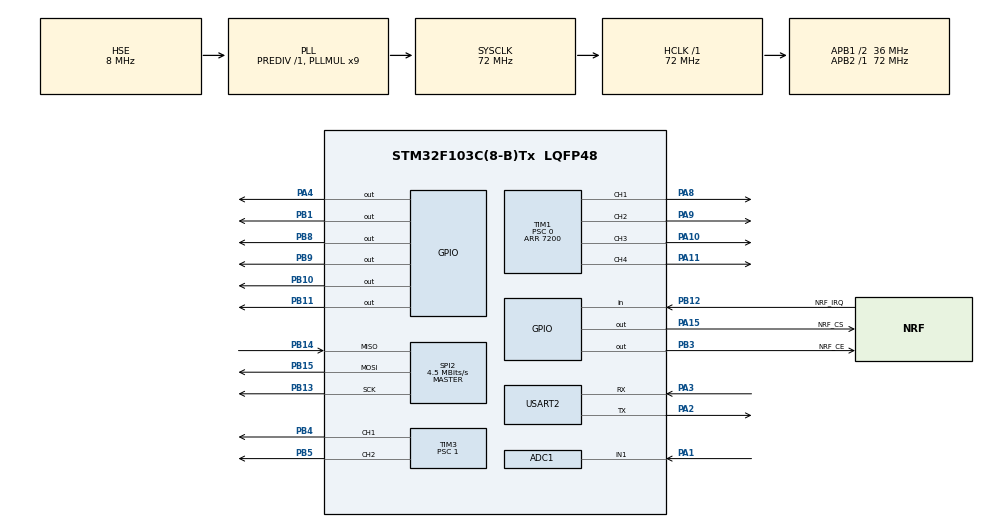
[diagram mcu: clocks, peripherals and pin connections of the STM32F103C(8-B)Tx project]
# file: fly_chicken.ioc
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ADC1.Channel-0\#ChannelRegularConversion=ADC_CHANNEL_1
ADC1.NbrOfConversionFlag=1
ADC1.Rank-0\#ChannelRegularConversion=1
ADC1.SamplingTime-0\#ChannelRegularConversion=ADC_SAMPLETIME_239CYCLES_5
ADC1.master=1
Mcu.Family=STM32F1
Mcu.Name=STM32F103C(8-B)Tx
Mcu.Package=LQFP48
NVIC.PriorityGroup=NVIC_PRIORITYGROUP_4
NVIC.TIM1_UP_IRQn=true\:0\:0\:false\:false\:true\:true\:true\:true
NVIC.TIM2_IRQn=true\:0\:0\:false\:false\:true\:true\:true\:true
PA1.Signal=ADCx_IN1
PA10.Signal=S_TIM1_CH3
PA11.Signal=S_TIM1_CH4
PA13.Mode=Serial_Wire
PA13.Signal=SYS_JTMS-SWDIO
PA14.Mode=Serial_Wire
PA14.Signal=SYS_JTCK-SWCLK
PA15.GPIO_Label=NRF_CS
PA15.GPIO_Speed=GPIO_SPEED_FREQ_HIGH
PA15.PinState=GPIO_PIN_SET
PA15.Signal=GPIO_Output
PA2.Mode=Asynchronous
PA2.Signal=USART2_TX
PA3.Mode=Asynchronous
PA3.Signal=USART2_RX
PA4.Signal=GPIO_Output
PA8.Signal=S_TIM1_CH1
PA9.Signal=S_TIM1_CH2
PB1.GPIO_Speed=GPIO_SPEED_FREQ_LOW
PB1.PinState=GPIO_PIN_RESET
PB1.Signal=GPIO_Output
PB10.Signal=GPIO_Output
PB11.Signal=GPIO_Output
PB12.GPIO_Label=NRF_IRQ
PB12.GPIO_PuPd=GPIO_PULLUP
PB12.Signal=GPIO_Input
PB13.Mode=Full_Duplex_Master
PB13.Signal=SPI2_SCK
PB14.Mode=Full_Duplex_Master
PB14.Signal=SPI2_MISO
PB15.Mode=Full_Duplex_Master
PB15.Signal=SPI2_MOSI
PB3.GPIO_Label=NRF_CE
PB3.GPIO_Speed=GPIO_SPEED_FREQ_HIGH
PB3.PinState=GPIO_PIN_SET
PB3.Signal=GPIO_Output
PB4.Signal=S_TIM3_CH1
PB5.Signal=S_TIM3_CH2
PB8.Signal=GPIO_Output
PB9.Signal=GPIO_Output
PD0-OSC_IN.Mode=HSE-External-Oscillator
PD0-OSC_IN.Signal=RCC_OSC_IN
PD1-OSC_OUT.Mode=HSE-External-Oscillator
PD1-OSC_OUT.Signal=RCC_OSC_OUT
ProjectManager.HeapSize=0x200
ProjectManager.StackSize=0x400
ProjectManager.TargetToolchain=MDK-ARM V5.32
RCC.AHBFreq_Value=72000000
RCC.APB1CLKDivider=RCC_HCLK_DIV2
RCC.APB1Freq_Value=36000000
RCC.APB1TimFreq_Value=72000000
RCC.APB2Freq_Value=72000000
RCC.APB2TimFreq_Value=72000000
RCC.HCLKFreq_Value=72000000
RCC.PLLMUL=RCC_PLL_MUL9
RCC.PLLSourceVirtual=RCC_PLLSOURCE_HSE
RCC.SYSCLKFreq_VALUE=72000000
RCC.SYSCLKSource=RCC_SYSCLKSOURCE_PLLCLK
RCC.USBFreq_Value=72000000
SH.ADCx_IN1.0=ADC1_IN1,IN1
SH.S_TIM1_CH1.0=TIM1_CH1,PWM Generation1 CH1
SH.S_TIM1_CH2.0=TIM1_CH2,PWM Generation2 CH2
SH.S_TIM1_CH3.0=TIM1_CH3,PWM Generation3 CH3
SH.S_TIM1_CH4.0=TIM1_CH4,PWM Generation4 CH4
SH.S_TIM3_CH1.0=TIM3_CH1,PWM Generation1 CH1
SH.S_TIM3_CH2.0=TIM3_CH2,PWM Generation2 CH2
SPI2.BaudRatePrescaler=SPI_BAUDRATEPRESCALER_8
SPI2.CalculateBaudRate=4.5 MBits/s
SPI2.Direction=SPI_DIRECTION_2LINES
SPI2.Mode=SPI_MODE_MASTER
SPI2.VirtualType=VM_MASTER
TIM1.AutoReloadPreload=TIM_AUTORELOAD_PRELOAD_ENABLE
TIM1.Channel-PWM\ Generation1\ CH1=TIM_CHANNEL_1
TIM1.Channel-PWM\ Generation2\ CH2=TIM_CHANNEL_2
TIM1.Channel-PWM\ Generation3\ CH3=TIM_CHANNEL_3
TIM1.Channel-PWM\ Generation4\ CH4=TIM_CHANNEL_4
TIM1.OCPolarity_1=TIM_OCPOLARITY_HIGH
TIM1.OCPolarity_2=TIM_OCPOLARITY_HIGH
TIM1.OCPolarity_3=TIM_OCPOLARITY_HIGH
TIM1.OCPolarity_4=TIM_OCPOLARITY_HIGH
TIM1.Period=7200
TIM1.Prescaler=0
TIM1.Pulse-PWM\ Generation1\ CH1=200
TIM1.Pulse-PWM\ Generation2\ CH2=200
TIM1.Pulse-PWM\ Generation3\ CH3=200
TIM1.Pulse-PWM\ Generation4\ CH4=200
TIM2.AutoReloadPreload=TIM_AUTORELOAD_PRELOAD_ENABLE
TIM2.Period=1000
TIM2.Prescaler=71
TIM3.Channel-PWM\ Generation1\ CH1=TIM_CHANNEL_1
TIM3.Channel-PWM\ Generation2\ CH2=TIM_CHANNEL_2
TIM3.Period=1000
TIM3.Prescaler=1
TIM3.Pulse-PWM\ Generation1\ CH1=500
TIM3.Pulse-PWM\ Generation2\ CH2=500
TIM4.Prescaler=71
USART2.VirtualMode=VM_ASYNC
VP_TIM1_VS_ClockSourceINT.Mode=Internal
VP_TIM2_VS_ClockSourceINT.Mode=Internal
VP_TIM3_VS_ClockSourceINT.Mode=Internal
VP_TIM4_VS_ClockSourceINT.Mode=Internal
board=custom

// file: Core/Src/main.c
/* USER CODE BEGIN Header */
/**
  ******************************************************************************
  * @file           : main.c
  * @brief          : Main program body
  ******************************************************************************
  * @attention
  *
  * Copyright (c) 2023 STMicroelectronics.
  * All rights reserved.
  *
  * This software is licensed under terms that can be found in the LICENSE file
  * in the root directory of this software component.
  * If no LICENSE file comes with this software, it is provided AS-IS.
  *
  ******************************************************************************
  */
/* USER CODE END Header */
#include "main.h"
#include "adc.h"
#include "spi.h"
#include "tim.h"
#include "usart.h"
#include "gpio.h"

void SystemClock_Config(void);

int main(void)
{

  /* MCU Configuration--------------------------------------------------------*/

  /* Reset of all peripherals, Initializes the Flash interface and the Systick. */
  HAL_Init();

  /* Configure the system clock */
  SystemClock_Config();

  /* USER CODE BEGIN SysInit */
// 初始化IO，防止PB3不能使用作为LED，PB4用于频率输出
//// 注意：修改前需要确保AFIO配置正确
// AFIO->MAPR = 0X02000000; // 使能复用功能，关闭JTAG保留SWD，释放PB3和PB4端口，用于自定义功能（参考STM32F103手册第118页）

  /* USER CODE END SysInit */

  /* Initialize all configured peripherals */
  MX_GPIO_Init();
  MX_TIM2_Init();
  MX_TIM3_Init();
  MX_USART2_UART_Init();
  MX_TIM4_Init();
  MX_TIM1_Init();
  MX_SPI2_Init();
  MX_ADC1_Init();
  /* USER CODE BEGIN 2 */
  HAL_TIM_Base_Start(&htim4);// 启动定时器4，用作普通定时
  HAL_TIM_Base_Start_IT(&htim2);//��ʱ��һ1ms�ж������������
	HAL_TIM_PWM_Start(&htim1,TIM_CHANNEL_1);
	HAL_TIM_PWM_Start(&htim1,TIM_CHANNEL_2);
	HAL_TIM_PWM_Start(&htim1,TIM_CHANNEL_3);
	HAL_TIM_PWM_Start(&htim1,TIM_CHANNEL_4);
  Motor_Set_Duty(0,0,0,0);

  printf("hallo\r\n");

   // *************************** 任务初始化
	 HAL_Delay(2000);
	 ALL_Init();
	 HAL_Delay(1000);
   MY_Task_Begin();         // 任务开始
//	 Motor_Set_Duty(100,100,100,100);

//    __HAL_TIM_SET_COMPARE(&htim1,TIM_CHANNEL_1,800);// 电机1初始占空比0
//		__HAL_TIM_SET_COMPARE(&htim1,TIM_CHANNEL_2,800);//m2
//		__HAL_TIM_SET_COMPARE(&htim1,TIM_CHANNEL_3,800);//m3
//		__HAL_TIM_SET_COMPARE(&htim1,TIM_CHANNEL_4,800);//m4
  /* USER CODE END 2 */

  /* Infinite loop */
  /* USER CODE BEGIN WHILE */

//	int32_t temp, press;
//	float pitch, roll, Altitude1,yaw,Altitude2;
//	static MPU_ACC_GYRO_DATA_STR   mpu_data;//角速度加速度原始数据

  while (1)
  {

	 	While_Loop();
	  HAL_Delay(500);

//		Imu_Euler_Angle_Update(50);// 获取当前欧拉角数据
//    Imu_Get_Euler_Angle_Data(&pitch, &roll, &yaw);
//    printf("fffffffffffffffff  %.2f, %.2f, %.2f\r\n", pitch, roll, yaw);// 打印角度数据（保留2位小数）
//printf("fffffffffffffffff  %d, %d, %d\r\n", (int)pitch, (int)roll, (int)yaw);

// mpu_data = My_Get_MPU_Data();
//    printf("【FFF.原始数据】ax=%.2f, ay=%.2f, az=%.2f | gx=%.2f, gy=%.2f, gz=%.2f\r\n",
//           mpu_data.ax, mpu_data.ay, mpu_data.az,
//           mpu_data.gx, mpu_data.gy, mpu_data.gz);

//	  printf("t:%d\r\n",TIM4->CNT);
//temp  = bmp280_GetTemperature();   // 必须先调用，更新 t_fine
//press = bmp280_GetPressure();
//		press = bmp280_GetPressure();
//		Altitude1 = bmp280_GetAltitude();
//		Altitude2 = bmp280_GetRelativeAltitude();
//		printf("T = %.2f C, P = %d Pa   A1:%.2f  A2:%.2f\r\n  ", temp / 100.0f, press,Altitude1,Altitude2);

    /* USER CODE END WHILE */

  }
}

void SystemClock_Config(void)
{
  RCC_OscInitTypeDef RCC_OscInitStruct = {0};
  RCC_ClkInitTypeDef RCC_ClkInitStruct = {0};
  RCC_PeriphCLKInitTypeDef PeriphClkInit = {0};

  /** Initializes the RCC Oscillators according to the specified parameters
  * in the RCC_OscInitTypeDef structure.
  */
  RCC_OscInitStruct.OscillatorType = RCC_OSCILLATORTYPE_HSE;
  RCC_OscInitStruct.HSEState = RCC_HSE_ON;
  RCC_OscInitStruct.HSEPredivValue = RCC_HSE_PREDIV_DIV1;
  RCC_OscInitStruct.HSIState = RCC_HSI_ON;
  RCC_OscInitStruct.PLL.PLLState = RCC_PLL_ON;
  RCC_OscInitStruct.PLL.PLLSource = RCC_PLLSOURCE_HSE;
  RCC_OscInitStruct.PLL.PLLMUL = RCC_PLL_MUL9;
  if (HAL_RCC_OscConfig(&RCC_OscInitStruct) != HAL_OK)
  {
    Error_Handler();
  }

  /** Initializes the CPU, AHB and APB buses clocks
  */
  RCC_ClkInitStruct.ClockType = RCC_CLOCKTYPE_HCLK|RCC_CLOCKTYPE_SYSCLK
                              |RCC_CLOCKTYPE_PCLK1|RCC_CLOCKTYPE_PCLK2;
  RCC_ClkInitStruct.SYSCLKSource = RCC_SYSCLKSOURCE_PLLCLK;
  RCC_ClkInitStruct.AHBCLKDivider = RCC_SYSCLK_DIV1;
  RCC_ClkInitStruct.APB1CLKDivider = RCC_HCLK_DIV2;
  RCC_ClkInitStruct.APB2CLKDivider = RCC_HCLK_DIV1;

  if (HAL_RCC_ClockConfig(&RCC_ClkInitStruct, FLASH_LATENCY_2) != HAL_OK)
  {
    Error_Handler();
  }
  PeriphClkInit.PeriphClockSelection = RCC_PERIPHCLK_ADC;
  PeriphClkInit.AdcClockSelection = RCC_ADCPCLK2_DIV2;
  if (HAL_RCCEx_PeriphCLKConfig(&PeriphClkInit) != HAL_OK)
  {
    Error_Handler();
  }
}

void Error_Handler(void)
{
  __disable_irq();
  while (1)
  {
  }
}
